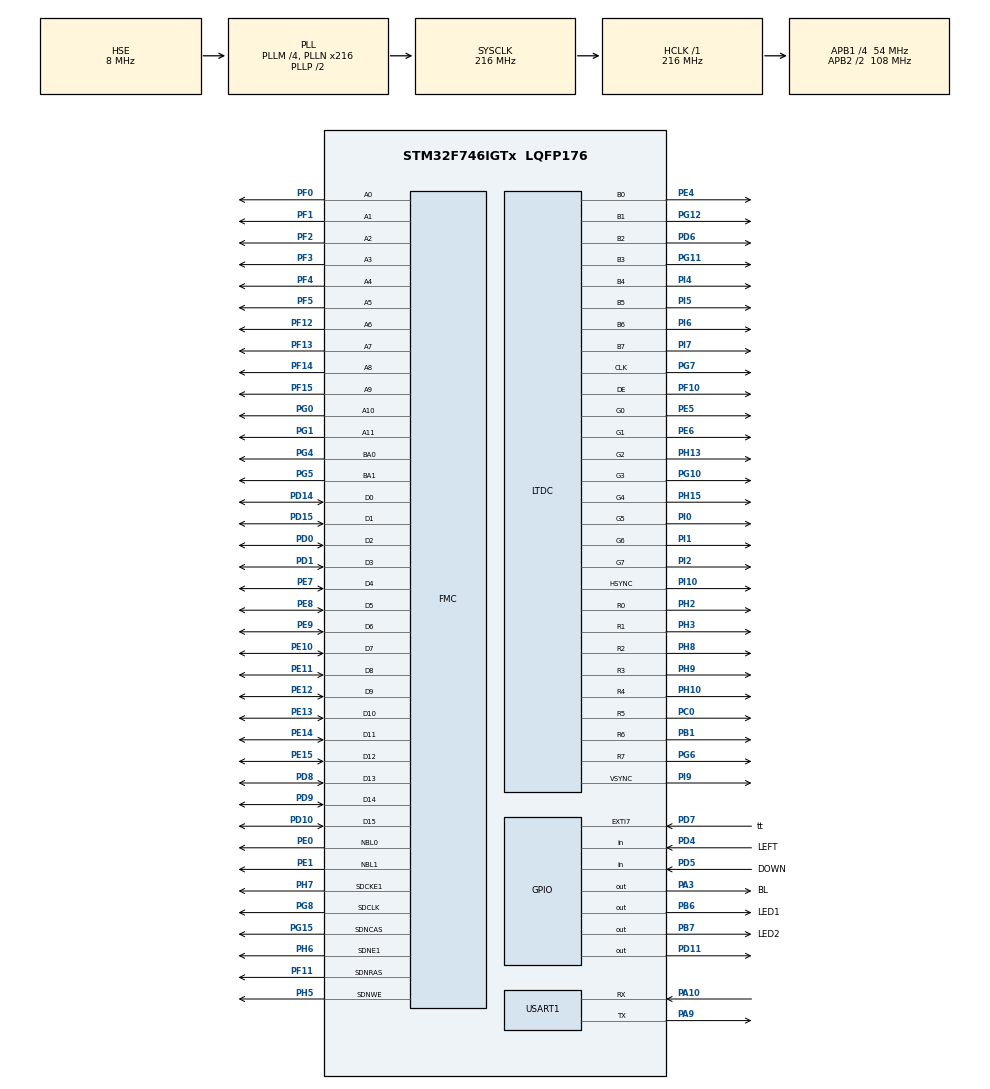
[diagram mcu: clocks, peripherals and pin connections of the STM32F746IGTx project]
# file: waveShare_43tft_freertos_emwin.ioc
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CORTEX_M7.CPU_DCache=Enabled
CORTEX_M7.CPU_ICache=Enabled
DMA2D.ColorMode=DMA2D_OUTPUT_RGB565
Dma.MEMTOMEM.0.Direction=DMA_MEMORY_TO_MEMORY
Dma.MEMTOMEM.0.FIFOMode=DMA_FIFOMODE_ENABLE
Dma.MEMTOMEM.0.FIFOThreshold=DMA_FIFO_THRESHOLD_FULL
Dma.MEMTOMEM.0.Instance=DMA2_Stream0
Dma.MEMTOMEM.0.MemBurst=DMA_MBURST_SINGLE
Dma.MEMTOMEM.0.MemDataAlignment=DMA_MDATAALIGN_BYTE
Dma.MEMTOMEM.0.MemInc=DMA_MINC_ENABLE
Dma.MEMTOMEM.0.Mode=DMA_NORMAL
Dma.MEMTOMEM.0.PeriphBurst=DMA_PBURST_SINGLE
Dma.MEMTOMEM.0.PeriphDataAlignment=DMA_PDATAALIGN_BYTE
Dma.MEMTOMEM.0.PeriphInc=DMA_PINC_ENABLE
Dma.MEMTOMEM.0.Priority=DMA_PRIORITY_LOW
Dma.Request0=MEMTOMEM
FMC.CASLatency1=FMC_SDRAM_CAS_LATENCY_2
FMC.ExitSelfRefreshDelay1=8
FMC.LoadToActiveDelay1=2
FMC.RCDDelay1=3
FMC.RPDelay1=2
FMC.RowCycleDelay1=7
FMC.SDClockPeriod1=FMC_SDRAM_CLOCK_PERIOD_2
FMC.SelfRefreshTime1=5
FMC.WriteRecoveryTime1=2
FREERTOS.Tasks01=defaultTask,0,128,StartDefaultTask,Default,NULL
FREERTOS.Timers01=CT_timer,scan_callback,osTimerPeriodic,Default,NULL,Dynamic,NULL
FREERTOS.configUSE_TIMERS=1
GRAPHICS.BSP.number=1
GRAPHICS.Xsize_PHYS=480
GRAPHICS.Ysize_PHYS=272
GRAPHICS0.BSP.STBoard=false
GRAPHICS0.BSP.api=Unknown
GRAPHICS0.BSP.i2caddr=0
GRAPHICS0.BSP.instance=PD11
GRAPHICS0.BSP.ip=GPIO
GRAPHICS0.BSP.mode=Output
GRAPHICS0.BSP.name=LCD Reset Pin XRES
GRAPHICS0.BSP.solution=PD11
LTDC.ActiveH=272
LTDC.ActiveW=480
LTDC.Alpha_L0=0xFF
LTDC.Alpha_L1=0
LTDC.BlendingFactor1_L0=LTDC_BLENDING_FACTOR1_PAxCA
LTDC.BlendingFactor1_L1=LTDC_BLENDING_FACTOR1_PAxCA
LTDC.BlendingFactor2_L0=LTDC_BLENDING_FACTOR2_PAxCA
LTDC.BlendingFactor2_L1=LTDC_BLENDING_FACTOR2_PAxCA
LTDC.FBStartAdress_L0=0xD0000000
LTDC.FBStartAdress_L1=0xD0200000
LTDC.HBP=43
LTDC.HFP=2
LTDC.HSync=2
LTDC.ImageHeight_L0=272
LTDC.ImageHeight_L1=600
LTDC.ImageWidth_L0=480
LTDC.ImageWidth_L1=1024
LTDC.Layers=0
LTDC.PixelFormat_L0=LTDC_PIXEL_FORMAT_RGB565
LTDC.PixelFormat_L1=LTDC_PIXEL_FORMAT_RGB565
LTDC.VBP=12
LTDC.VFP=1
LTDC.VSync=2
LTDC.WindowX1_L0=480
LTDC.WindowX1_L1=1024
LTDC.WindowY1_L0=272
LTDC.WindowY1_L1=600
Mcu.Family=STM32F7
Mcu.Name=STM32F746IGTx
Mcu.Package=LQFP176
NVIC.DMA2D_IRQn=true\:5\:0\:false\:false\:true\:true\:true\:true
NVIC.EXTI9_5_IRQn=true\:5\:0\:false\:false\:true\:true\:true\:true
NVIC.LTDC_IRQn=true\:5\:0\:false\:false\:true\:true\:true\:true
NVIC.PriorityGroup=NVIC_PRIORITYGROUP_4
NVIC.TIM1_UP_TIM10_IRQn=true\:0\:0\:false\:false\:true\:false\:false\:true
NVIC.TimeBase=TIM1_UP_TIM10_IRQn
NVIC.TimeBaseIP=TIM1
PA10.Mode=Asynchronous
PA10.Signal=USART1_RX
PA3.GPIO_Label=BL
PA3.Signal=GPIO_Output
PA9.Mode=Asynchronous
PA9.Signal=USART1_TX
PB1.GPIO_Speed=GPIO_SPEED_FREQ_HIGH
PB1.Mode=RGB888
PB1.Signal=LTDC_R6
PB6.GPIO_Label=LED1
PB6.Signal=GPIO_Output
PB7.GPIO_Label=LED2
PB7.Signal=GPIO_Output
PC0.GPIO_Speed=GPIO_SPEED_FREQ_HIGH
PC0.Mode=RGB888
PC0.Signal=LTDC_R5
PC14/OSC32_IN.Mode=LSE-External-Oscillator
PC14/OSC32_IN.Signal=RCC_OSC32_IN
PC15/OSC32_OUT.Mode=LSE-External-Oscillator
PC15/OSC32_OUT.Signal=RCC_OSC32_OUT
PD0.Signal=FMC_D2_DA2
PD1.Signal=FMC_D3_DA3
PD10.Signal=FMC_D15_DA15
PD11.Signal=GPIO_Output
PD14.Signal=FMC_D0_DA0
PD15.Signal=FMC_D1_DA1
PD4.GPIO_Label=LEFT
PD4.Signal=GPIO_Input
PD5.GPIO_Label=DOWN
PD5.Signal=GPIO_Input
PD6.GPIO_Speed=GPIO_SPEED_FREQ_HIGH
PD6.Mode=RGB888
PD6.Signal=LTDC_B2
PD7.GPIO_Label=tt
PD7.GPIO_ModeDefaultEXTI=GPIO_MODE_IT_FALLING
PD7.Signal=GPXTI7
PD8.Signal=FMC_D13_DA13
PD9.Signal=FMC_D14_DA14
PE0.Signal=FMC_NBL0
PE1.Signal=FMC_NBL1
PE10.Signal=FMC_D7_DA7
PE11.Signal=FMC_D8_DA8
PE12.Signal=FMC_D9_DA9
PE13.Signal=FMC_D10_DA10
PE14.Signal=FMC_D11_DA11
PE15.Signal=FMC_D12_DA12
PE4.GPIO_Speed=GPIO_SPEED_FREQ_HIGH
PE4.Mode=RGB888
PE4.Signal=LTDC_B0
PE5.GPIO_Speed=GPIO_SPEED_FREQ_HIGH
PE5.Mode=RGB888
PE5.Signal=LTDC_G0
PE6.GPIO_Speed=GPIO_SPEED_FREQ_HIGH
PE6.Mode=RGB888
PE6.Signal=LTDC_G1
PE7.Signal=FMC_D4_DA4
PE8.Signal=FMC_D5_DA5
PE9.Signal=FMC_D6_DA6
PF0.Signal=FMC_A0
PF1.Signal=FMC_A1
PF10.GPIO_Speed=GPIO_SPEED_FREQ_HIGH
PF10.Mode=RGB888
PF10.Signal=LTDC_DE
PF11.Signal=FMC_SDNRAS
PF12.Signal=FMC_A6
PF13.Signal=FMC_A7
PF14.Signal=FMC_A8
PF15.Signal=FMC_A9
PF2.Signal=FMC_A2
PF3.Signal=FMC_A3
PF4.Signal=FMC_A4
PF5.Signal=FMC_A5
PG0.Signal=FMC_A10
PG1.Signal=FMC_A11
PG10.GPIO_Speed=GPIO_SPEED_FREQ_HIGH
PG10.Mode=RGB888
PG10.Signal=LTDC_G3
PG11.GPIO_Speed=GPIO_SPEED_FREQ_HIGH
PG11.Mode=RGB888
PG11.Signal=LTDC_B3
PG12.GPIO_Speed=GPIO_SPEED_FREQ_HIGH
PG12.Mode=RGB888
PG12.Signal=LTDC_B1
PG15.Signal=FMC_SDNCAS
PG4.Signal=FMC_A14_BA0
PG5.Signal=FMC_A15_BA1
PG6.GPIO_Speed=GPIO_SPEED_FREQ_HIGH
PG6.Mode=RGB888
PG6.Signal=LTDC_R7
PG7.GPIO_Speed=GPIO_SPEED_FREQ_HIGH
PG7.Mode=RGB888
PG7.Signal=LTDC_CLK
PG8.Signal=FMC_SDCLK
PH0/OSC_IN.Mode=HSE-External-Oscillator
PH0/OSC_IN.Signal=RCC_OSC_IN
PH1/OSC_OUT.Mode=HSE-External-Oscillator
PH1/OSC_OUT.Signal=RCC_OSC_OUT
PH10.GPIO_Speed=GPIO_SPEED_FREQ_HIGH
PH10.Mode=RGB888
PH10.Signal=LTDC_R4
PH13.GPIO_Speed=GPIO_SPEED_FREQ_HIGH
PH13.Mode=RGB888
PH13.Signal=LTDC_G2
PH15.GPIO_Speed=GPIO_SPEED_FREQ_HIGH
PH15.Mode=RGB888
PH15.Signal=LTDC_G4
PH2.GPIO_Speed=GPIO_SPEED_FREQ_HIGH
PH2.Mode=RGB888
PH2.Signal=LTDC_R0
PH3.GPIO_Speed=GPIO_SPEED_FREQ_HIGH
PH3.Mode=RGB888
PH3.Signal=LTDC_R1
PH5.Signal=FMC_SDNWE
PH6.Mode=SdramChipSelect2_1
PH6.Signal=FMC_SDNE1
PH7.Mode=SdramChipSelect2_1
PH7.Signal=FMC_SDCKE1
PH8.GPIO_Speed=GPIO_SPEED_FREQ_HIGH
PH8.Mode=RGB888
PH8.Signal=LTDC_R2
PH9.GPIO_Speed=GPIO_SPEED_FREQ_HIGH
PH9.Mode=RGB888
PH9.Signal=LTDC_R3
PI0.GPIO_Speed=GPIO_SPEED_FREQ_HIGH
PI0.Mode=RGB888
PI0.Signal=LTDC_G5
PI1.GPIO_Speed=GPIO_SPEED_FREQ_HIGH
PI1.Mode=RGB888
PI1.Signal=LTDC_G6
PI10.GPIO_Speed=GPIO_SPEED_FREQ_HIGH
PI10.Mode=RGB888
PI10.Signal=LTDC_HSYNC
PI2.GPIO_Speed=GPIO_SPEED_FREQ_HIGH
PI2.Mode=RGB888
PI2.Signal=LTDC_G7
PI4.GPIO_Speed=GPIO_SPEED_FREQ_HIGH
PI4.Mode=RGB888
PI4.Signal=LTDC_B4
PI5.GPIO_Speed=GPIO_SPEED_FREQ_HIGH
PI5.Mode=RGB888
PI5.Signal=LTDC_B5
PI6.GPIO_Speed=GPIO_SPEED_FREQ_HIGH
PI6.Mode=RGB888
PI6.Signal=LTDC_B6
PI7.GPIO_Speed=GPIO_SPEED_FREQ_HIGH
PI7.Mode=RGB888
PI7.Signal=LTDC_B7
PI9.GPIO_Speed=GPIO_SPEED_FREQ_HIGH
PI9.Mode=RGB888
PI9.Signal=LTDC_VSYNC
ProjectManager.HeapSize=0x200
ProjectManager.StackSize=0x300
ProjectManager.TargetToolchain=MDK-ARM V5.27
RCC.AHBFreq_Value=216000000
RCC.APB1CLKDivider=RCC_HCLK_DIV4
RCC.APB1Freq_Value=54000000
RCC.APB1TimFreq_Value=108000000
RCC.APB2CLKDivider=RCC_HCLK_DIV2
RCC.APB2Freq_Value=108000000
RCC.APB2TimFreq_Value=216000000
RCC.CortexFreq_Value=216000000
RCC.HCLKFreq_Value=216000000
RCC.HSE_VALUE=8000000
RCC.HSI_VALUE=16000000
RCC.PLLM=4
RCC.PLLN=216
RCC.PLLSAIN=60
RCC.PLLSAIR=5
RCC.PLLSourceVirtual=RCC_PLLSOURCE_HSE
RCC.SYSCLKFreq_VALUE=216000000
RCC.SYSCLKSource=RCC_SYSCLKSOURCE_PLLCLK
RCC.USBFreq_Value=216000000
RCC.VCOOutputFreq_Value=432000000
SH.FMC_A0.0=FMC_A0,12b-sda1
SH.FMC_A1.0=FMC_A1,12b-sda1
SH.FMC_A10.0=FMC_A10,12b-sda1
SH.FMC_A11.0=FMC_A11,12b-sda1
SH.FMC_A14_BA0.0=FMC_BA0,FourSdramBanks1
SH.FMC_A15_BA1.0=FMC_BA1,FourSdramBanks1
SH.FMC_A2.0=FMC_A2,12b-sda1
SH.FMC_A3.0=FMC_A3,12b-sda1
SH.FMC_A4.0=FMC_A4,12b-sda1
SH.FMC_A5.0=FMC_A5,12b-sda1
SH.FMC_A6.0=FMC_A6,12b-sda1
SH.FMC_A7.0=FMC_A7,12b-sda1
SH.FMC_A8.0=FMC_A8,12b-sda1
SH.FMC_A9.0=FMC_A9,12b-sda1
SH.FMC_D0_DA0.0=FMC_D0,sd-16b-d1
SH.FMC_D10_DA10.0=FMC_D10,sd-16b-d1
SH.FMC_D11_DA11.0=FMC_D11,sd-16b-d1
SH.FMC_D12_DA12.0=FMC_D12,sd-16b-d1
SH.FMC_D13_DA13.0=FMC_D13,sd-16b-d1
SH.FMC_D14_DA14.0=FMC_D14,sd-16b-d1
SH.FMC_D15_DA15.0=FMC_D15,sd-16b-d1
SH.FMC_D1_DA1.0=FMC_D1,sd-16b-d1
SH.FMC_D2_DA2.0=FMC_DA2
SH.FMC_D2_DA2.1=FMC_D2,sd-16b-d1
SH.FMC_D3_DA3.0=FMC_DA3
SH.FMC_D3_DA3.1=FMC_D3,sd-16b-d1
SH.FMC_D4_DA4.0=FMC_D4,sd-16b-d1
SH.FMC_D5_DA5.0=FMC_D5,sd-16b-d1
SH.FMC_D6_DA6.0=FMC_D6,sd-16b-d1
SH.FMC_D7_DA7.0=FMC_D7,sd-16b-d1
SH.FMC_D8_DA8.0=FMC_D8,sd-16b-d1
SH.FMC_D9_DA9.0=FMC_D9,sd-16b-d1
SH.FMC_NBL0.0=FMC_NBL0,Sd2ByteEnable1
SH.FMC_NBL1.0=FMC_NBL1,Sd2ByteEnable1
SH.FMC_SDCLK.0=FMC_SDCLK,12b-sda1
SH.FMC_SDNCAS.0=FMC_SDNCAS,12b-sda1
SH.FMC_SDNRAS.0=FMC_SDNRAS,12b-sda1
SH.FMC_SDNWE.0=FMC_SDNWE,12b-sda1
USART1.VirtualMode-Asynchronous=VM_ASYNC
VP_CRC_VS_CRC.Mode=CRC_Activate
VP_DMA2D_VS_DMA2D.Mode=DMA2D_Activate
VP_FREERTOS_VS_CMSIS_V1.Mode=CMSIS_V1
VP_GRAPHICS_VS-DisplayInterface-LTDC.Mode=Display Parallel Interface using LTDC
VP_GRAPHICS_VS-STemWin.Mode=STemWin
VP_SYS_VS_tim1.Mode=TIM1
board=custom

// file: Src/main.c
/* USER CODE BEGIN Header */
/**
  ******************************************************************************
  * @file           : main.c
  * @brief          : Main program body
  ******************************************************************************
  * @attention
  *
  * <h2><center>&copy; Copyright (c) 2021 STMicroelectronics.
  * All rights reserved.</center></h2>
  *
  * This software component is licensed by ST under Ultimate Liberty license
  * SLA0044, the "License"; You may not use this file except in compliance with
  * the License. You may obtain a copy of the License at:
  *                             www.st.com/SLA0044
  *
  ******************************************************************************
  */
/* USER CODE END Header */

#include "main.h"
#include "cmsis_os.h"
#include "crc.h"
#include "dma.h"
#include "usart.h"
#include "gpio.h"

/* USER CODE BEGIN PM */
	#define buff_len					32
	#define	buff_offset				0x40000
	#define	extern_ram_base 	0xD0000000

/* USER CODE END PM */

/* USER CODE BEGIN PV */
uint8_t   extern_ram_buffer1[buff_len]   __attribute__ ((at(extern_ram_base + buff_offset)));
uint8_t   extern_ram_buffer2[buff_len]   __attribute__ ((at(extern_ram_base + buff_offset + buff_offset + 16)));

/* USER CODE END PV */

void SystemClock_Config(void);
void MX_FREERTOS_Init(void);
extern void GRAPHICS_HW_Init(void);
extern void GRAPHICS_Init(void);
extern void GRAPHICS_MainTask(void);

int main(void)
{

  /* Enable I-Cache---------------------------------------------------------*/
  SCB_EnableICache();

  /* Enable D-Cache---------------------------------------------------------*/
  SCB_EnableDCache();

  /* MCU Configuration--------------------------------------------------------*/

  /* Reset of all peripherals, Initializes the Flash interface and the Systick. */
  HAL_Init();

  /* Configure the system clock */
  SystemClock_Config();

  /* Initialize all configured peripherals */
  MX_GPIO_Init();
  MX_USART1_UART_Init();
  MX_DMA_Init();
  MX_CRC_Init();
  /* USER CODE BEGIN 2 */
	for(uint16_t i = 0; i < buff_len; i++) {extern_ram_buffer1[i]= i; printf("extern data is %d\r\n", extern_ram_buffer1[i]);}

	for(uint16_t i = 0; i < buff_len; i++) {extern_ram_buffer2[i] = extern_ram_buffer1[i]; printf("extern copied ram is %d \r\n", extern_ram_buffer2[i]);}
  /* USER CODE END 2 */

/* Initialise the graphical hardware */
  GRAPHICS_HW_Init();

  /* Initialise the graphical stack engine */
  GRAPHICS_Init();

  /* Call init function for freertos objects (in freertos.c) */
  MX_FREERTOS_Init();

  /* Start scheduler */
  osKernelStart();

  /* We should never get here as control is now taken by the scheduler */

  /* Infinite loop */
  while (1)
  {

  }
}

void SystemClock_Config(void)
{
  RCC_OscInitTypeDef RCC_OscInitStruct = {0};
  RCC_ClkInitTypeDef RCC_ClkInitStruct = {0};
  RCC_PeriphCLKInitTypeDef PeriphClkInitStruct = {0};

  /** Configure LSE Drive Capability
  */
  HAL_PWR_EnableBkUpAccess();
  /** Configure the main internal regulator output voltage
  */
  __HAL_RCC_PWR_CLK_ENABLE();
  __HAL_PWR_VOLTAGESCALING_CONFIG(PWR_REGULATOR_VOLTAGE_SCALE1);
  /** Initializes the CPU, AHB and APB busses clocks
  */
  RCC_OscInitStruct.OscillatorType = RCC_OSCILLATORTYPE_HSE;
  RCC_OscInitStruct.HSEState = RCC_HSE_ON;
  RCC_OscInitStruct.PLL.PLLState = RCC_PLL_ON;
  RCC_OscInitStruct.PLL.PLLSource = RCC_PLLSOURCE_HSE;
  RCC_OscInitStruct.PLL.PLLM = 4;
  RCC_OscInitStruct.PLL.PLLN = 216;
  RCC_OscInitStruct.PLL.PLLP = RCC_PLLP_DIV2;
  RCC_OscInitStruct.PLL.PLLQ = 2;
  if (HAL_RCC_OscConfig(&RCC_OscInitStruct) != HAL_OK)
  {
    Error_Handler();
  }
  /** Activate the Over-Drive mode
  */
  if (HAL_PWREx_EnableOverDrive() != HAL_OK)
  {
    Error_Handler();
  }
  /** Initializes the CPU, AHB and APB busses clocks
  */
  RCC_ClkInitStruct.ClockType = RCC_CLOCKTYPE_HCLK|RCC_CLOCKTYPE_SYSCLK
                              |RCC_CLOCKTYPE_PCLK1|RCC_CLOCKTYPE_PCLK2;
  RCC_ClkInitStruct.SYSCLKSource = RCC_SYSCLKSOURCE_PLLCLK;
  RCC_ClkInitStruct.AHBCLKDivider = RCC_SYSCLK_DIV1;
  RCC_ClkInitStruct.APB1CLKDivider = RCC_HCLK_DIV4;
  RCC_ClkInitStruct.APB2CLKDivider = RCC_HCLK_DIV2;

  if (HAL_RCC_ClockConfig(&RCC_ClkInitStruct, FLASH_LATENCY_7) != HAL_OK)
  {
    Error_Handler();
  }
  PeriphClkInitStruct.PeriphClockSelection = RCC_PERIPHCLK_LTDC|RCC_PERIPHCLK_USART1;
  PeriphClkInitStruct.PLLSAI.PLLSAIN = 60;
  PeriphClkInitStruct.PLLSAI.PLLSAIR = 5;
  PeriphClkInitStruct.PLLSAI.PLLSAIQ = 2;
  PeriphClkInitStruct.PLLSAI.PLLSAIP = RCC_PLLSAIP_DIV2;
  PeriphClkInitStruct.PLLSAIDivQ = 1;
  PeriphClkInitStruct.PLLSAIDivR = RCC_PLLSAIDIVR_2;
  PeriphClkInitStruct.Usart1ClockSelection = RCC_USART1CLKSOURCE_PCLK2;
  if (HAL_RCCEx_PeriphCLKConfig(&PeriphClkInitStruct) != HAL_OK)
  {
    Error_Handler();
  }
}

void HAL_TIM_PeriodElapsedCallback(TIM_HandleTypeDef *htim)
{
  if (htim->Instance == TIM1) {
    HAL_IncTick();
  }
}

void Error_Handler(void)
{
}

/************************ (C) COPYRIGHT STMicroelectronics *****END OF FILE****/

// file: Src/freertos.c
/* USER CODE BEGIN Header */
/**
  ******************************************************************************
  * File Name          : freertos.c
  * Description        : Code for freertos applications
  ******************************************************************************
  * @attention
  *
  * <h2><center>&copy; Copyright (c) 2021 STMicroelectronics.
  * All rights reserved.</center></h2>
  *
  * This software component is licensed by ST under Ultimate Liberty license
  * SLA0044, the "License"; You may not use this file except in compliance with
  * the License. You may obtain a copy of the License at:
  *                             www.st.com/SLA0044
  *
  ******************************************************************************
  */
/* USER CODE END Header */

#include "FreeRTOS.h"
#include "task.h"
#include "main.h"
#include "cmsis_os.h"
#include "gt911.h"

osThreadId defaultTaskHandle;
osTimerId CT_timerHandle;

void StartDefaultTask(void const * argument);
void scan_callback(void const * argument);

extern void GRAPHICS_MainTask(void);
void MX_FREERTOS_Init(void); /* (MISRA C 2004 rule 8.1) */

/* GetIdleTaskMemory prototype (linked to static allocation support) */
void vApplicationGetIdleTaskMemory( StaticTask_t **ppxIdleTaskTCBBuffer, StackType_t **ppxIdleTaskStackBuffer, uint32_t *pulIdleTaskStackSize );

/* GetTimerTaskMemory prototype (linked to static allocation support) */
void vApplicationGetTimerTaskMemory( StaticTask_t **ppxTimerTaskTCBBuffer, StackType_t **ppxTimerTaskStackBuffer, uint32_t *pulTimerTaskStackSize );

/* USER CODE BEGIN GET_IDLE_TASK_MEMORY */
static StaticTask_t xIdleTaskTCBBuffer;
static StackType_t xIdleStack[configMINIMAL_STACK_SIZE];

void vApplicationGetIdleTaskMemory( StaticTask_t **ppxIdleTaskTCBBuffer, StackType_t **ppxIdleTaskStackBuffer, uint32_t *pulIdleTaskStackSize )
{
  *ppxIdleTaskTCBBuffer = &xIdleTaskTCBBuffer;
  *ppxIdleTaskStackBuffer = &xIdleStack[0];
  *pulIdleTaskStackSize = configMINIMAL_STACK_SIZE;
  /* place for user code */
}
/* USER CODE END GET_IDLE_TASK_MEMORY */

/* USER CODE BEGIN GET_TIMER_TASK_MEMORY */
static StaticTask_t xTimerTaskTCBBuffer;
static StackType_t xTimerStack[configTIMER_TASK_STACK_DEPTH];

void vApplicationGetTimerTaskMemory( StaticTask_t **ppxTimerTaskTCBBuffer, StackType_t **ppxTimerTaskStackBuffer, uint32_t *pulTimerTaskStackSize )
{
  *ppxTimerTaskTCBBuffer = &xTimerTaskTCBBuffer;
  *ppxTimerTaskStackBuffer = &xTimerStack[0];
  *pulTimerTaskStackSize = configTIMER_TASK_STACK_DEPTH;
  /* place for user code */
}
/* USER CODE END GET_TIMER_TASK_MEMORY */

void MX_FREERTOS_Init(void) {
	GT911_Init();

  /* Create the timer(s) */
  /* definition and creation of CT_timer */
  osTimerDef(CT_timer, scan_callback);
  CT_timerHandle = osTimerCreate(osTimer(CT_timer), osTimerPeriodic, NULL);
	osTimerStart(CT_timerHandle, 16);

  /* Create the thread(s) */
  /* definition and creation of defaultTask */
  osThreadDef(defaultTask, StartDefaultTask, osPriorityNormal, 0, 512);
  defaultTaskHandle = osThreadCreate(osThread(defaultTask), NULL);

}

void StartDefaultTask(void const * argument)
{
/* Graphic application */
  GRAPHICS_MainTask();
  /* USER CODE BEGIN StartDefaultTask */
  /* Infinite loop */
  for(;;)
  {
    osDelay(10);
  }
  /* USER CODE END StartDefaultTask */
}

/* scan_callback function */
void scan_callback(void const * argument)
{
  /* USER CODE BEGIN scan_callback */
  //HAL_UART_Transmit(&huart1, (uint8_t *)"timer\r\n", 19,100);
	GT911_Scan();
	osDelay(15);
  /* USER CODE END scan_callback */
}

/************************ (C) COPYRIGHT STMicroelectronics *****END OF FILE****/
void HAL_GPIO_EXTI_Callback(uint16_t GPIO_Pin)
{
	if (GPIO_Pin == tt_Pin)
		Dev_Now.Touch = 1;
}
